AUTOSAR XML (schema 4-2-2)
standard types defined: uint64, uint64_DataConstr
package /ComponentTypes
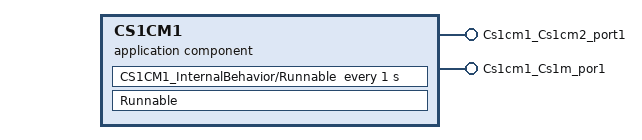
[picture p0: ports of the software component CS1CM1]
  application sw component type CS1CM1
    provide port Cs1cm1_Cs1cm2_port1: nonqueued-sender-com-spec{data-element=Cs1cm1_Cs1cm2_port1/Element, init-value=0}, provided-interface=Cs1cm1_Cs1cm2_port1
    provide port Cs1cm1_Cs1m_por1: nonqueued-sender-com-spec{data-element=Cs1cm1_Cs1m_por1/Element, init-value=0}, provided-interface=Cs1cm1_Cs1m_por1
    behavior CS1CM1_InternalBehavior
      timing event TMT_Runnable: start-on-event=CS1CM1_InternalBehavior/Runnable, period=1
      runnable Runnable: minimum-start-interval=1
        data-send-points:
          access SEND_Cs1cm1_Cs1cm2_port1_Element: accessed-variable=Cs1cm1_Cs1cm2_port1.Element
          access SEND_Cs1cm1_Cs1m_por1_Element: accessed-variable=Cs1cm1_Cs1m_por1.Element
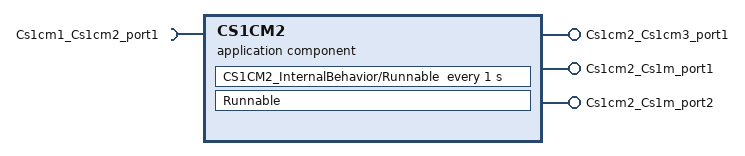
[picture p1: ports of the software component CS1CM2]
  application sw component type CS1CM2
    provide port Cs1cm2_Cs1cm3_port1: server-com-spec{operation=Cs1cm2_Cs1cm3_port1/Operation, queue-length=1}, provided-interface=Cs1cm2_Cs1cm3_port1
    provide port Cs1cm2_Cs1m_port1: nonqueued-sender-com-spec{data-element=Cs1cm2_Cs1m_port1/Element, init-value=0}, provided-interface=Cs1cm2_Cs1m_port1
    provide port Cs1cm2_Cs1m_port2: nonqueued-sender-com-spec{data-element=Cs1cm2_Cs1m_port2/Element, init-value=0}, provided-interface=Cs1cm2_Cs1m_port2
    require port Cs1cm1_Cs1cm2_port1: nonqueued-receiver-com-spec{data-element=Cs1cm1_Cs1cm2_port1/Element, filter=data-filter-type=ALWAYS, init-value=0}, required-interface=Cs1cm1_Cs1cm2_port1
    behavior CS1CM2_InternalBehavior
      timing event TMT_Runnable: start-on-event=CS1CM2_InternalBehavior/Runnable, period=1
      runnable Runnable: minimum-start-interval=1
        data-receive-point-by-arguments:
          access REC_Cs1cm1_Cs1cm2_port1_Element: accessed-variable=Cs1cm1_Cs1cm2_port1.Element
        data-send-points:
          access SEND_Cs1cm2_Cs1m_port1_Element: accessed-variable=Cs1cm2_Cs1m_port1.Element
          access SEND_Cs1cm2_Cs1m_port2_Element: accessed-variable=Cs1cm2_Cs1m_port2.Element
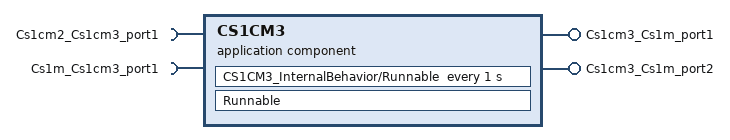
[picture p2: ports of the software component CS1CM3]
  application sw component type CS1CM3
    provide port Cs1cm3_Cs1m_port1: nonqueued-sender-com-spec{data-element=Cs1cm3_Cs1m_port1/Element, init-value=0}, provided-interface=Cs1cm3_Cs1m_port1
    provide port Cs1cm3_Cs1m_port2: nonqueued-sender-com-spec{data-element=Cs1cm3_Cs1m_port2/Element, init-value=0}, provided-interface=Cs1cm3_Cs1m_port2
    require port Cs1cm2_Cs1cm3_port1: client-com-spec=Cs1cm2_Cs1cm3_port1/Operation, required-interface=Cs1cm2_Cs1cm3_port1
    require port Cs1m_Cs1cm3_port1: nonqueued-receiver-com-spec{data-element=Cs1m_Cs1cm3_port1/Element, filter=data-filter-type=ALWAYS, init-value=0}, required-interface=Cs1m_Cs1cm3_port1
    behavior CS1CM3_InternalBehavior
      timing event TMT_Runnable: start-on-event=CS1CM3_InternalBehavior/Runnable, period=1
      runnable Runnable: minimum-start-interval=1
        data-receive-point-by-arguments:
          access REC_Cs1m_Cs1cm3_port1_Element: accessed-variable=Cs1m_Cs1cm3_port1.Element
        data-send-points:
          access SEND_Cs1cm3_Cs1m_port1_Element: accessed-variable=Cs1cm3_Cs1m_port1.Element
          access SEND_Cs1cm3_Cs1m_port2_Element: accessed-variable=Cs1cm3_Cs1m_port2.Element
        sync call SC_Cs1cm2_Cs1cm3_port1_Operation: operation=Cs1cm2_Cs1cm3_port1.Operation, timeout=0
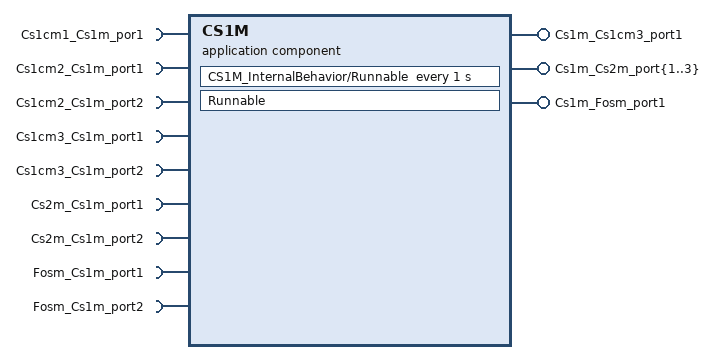
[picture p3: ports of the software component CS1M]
  application sw component type CS1M
    5 x provide port:
      Cs1m_Cs1cm3_port1: nonqueued-sender-com-spec{data-element=Cs1m_Cs1cm3_port1/Element, init-value=0}, provided-interface=Cs1m_Cs1cm3_port1
      Cs1m_Cs2m_port{1..3}: nonqueued-sender-com-spec{data-element=Cs1m_Cs2m_port{1..3}/Element, init-value=0}, provided-interface=Cs1m_Cs2m_port{1..3}
      Cs1m_Fosm_port1: nonqueued-sender-com-spec{data-element=Cs1m_Fosm_port1/Element, init-value=0}, provided-interface=Cs1m_Fosm_port1
    9 x require port:
      Cs1cm1_Cs1m_por1: nonqueued-receiver-com-spec{data-element=Cs1cm1_Cs1m_por1/Element, filter=data-filter-type=ALWAYS, init-value=0}, required-interface=Cs1cm1_Cs1m_por1
      Cs1cm2_Cs1m_port1: nonqueued-receiver-com-spec{data-element=Cs1cm2_Cs1m_port1/Element, filter=data-filter-type=ALWAYS, init-value=0}, required-interface=Cs1cm2_Cs1m_port1
      Cs1cm2_Cs1m_port2: nonqueued-receiver-com-spec{data-element=Cs1cm2_Cs1m_port2/Element, filter=data-filter-type=ALWAYS, init-value=0}, required-interface=Cs1cm2_Cs1m_port2
      Cs1cm3_Cs1m_port1: nonqueued-receiver-com-spec{data-element=Cs1cm3_Cs1m_port1/Element, filter=data-filter-type=ALWAYS, init-value=0}, required-interface=Cs1cm3_Cs1m_port1
      Cs1cm3_Cs1m_port2: nonqueued-receiver-com-spec{data-element=Cs1cm3_Cs1m_port2/Element, filter=data-filter-type=ALWAYS, init-value=0}, required-interface=Cs1cm3_Cs1m_port2
      Cs2m_Cs1m_port1: nonqueued-receiver-com-spec{data-element=Cs2m_Cs1m_port1/Element, filter=data-filter-type=ALWAYS, init-value=0}, required-interface=Cs2m_Cs1m_port1
      Cs2m_Cs1m_port2: nonqueued-receiver-com-spec{data-element=Cs2m_Cs1m_port2/Element, filter=data-filter-type=ALWAYS, init-value=0}, required-interface=Cs2m_Cs1m_port2
      Fosm_Cs1m_port1: nonqueued-receiver-com-spec{data-element=Fosm_Cs1m_port1/Element, filter=data-filter-type=ALWAYS, init-value=0}, required-interface=Fosm_Cs1m_port1
      Fosm_Cs1m_port2: nonqueued-receiver-com-spec{data-element=Fosm_Cs1m_port2/Element, filter=data-filter-type=ALWAYS, init-value=0}, required-interface=Fosm_Cs1m_port2
    behavior CS1M_InternalBehavior
      timing event TMT_Runnable: start-on-event=CS1M_InternalBehavior/Runnable, period=1
      runnable Runnable: minimum-start-interval=1
        data-receive-point-by-arguments:
          9 x access:
            REC_Cs1cm1_Cs1m_por1_Element: accessed-variable=Cs1cm1_Cs1m_por1.Element
            REC_Cs1cm2_Cs1m_port1_Element: accessed-variable=Cs1cm2_Cs1m_port1.Element
            REC_Cs1cm2_Cs1m_port2_Element: accessed-variable=Cs1cm2_Cs1m_port2.Element
            REC_Cs1cm3_Cs1m_port1_Element: accessed-variable=Cs1cm3_Cs1m_port1.Element
            REC_Cs1cm3_Cs1m_port2_Element: accessed-variable=Cs1cm3_Cs1m_port2.Element
            REC_Cs2m_Cs1m_port1_Element: accessed-variable=Cs2m_Cs1m_port1.Element
            REC_Cs2m_Cs1m_port2_Element: accessed-variable=Cs2m_Cs1m_port2.Element
            REC_Fosm_Cs1m_port1_Element: accessed-variable=Fosm_Cs1m_port1.Element
            REC_Fosm_Cs1m_port2_Element: accessed-variable=Fosm_Cs1m_port2.Element
        data-send-points:
          5 x access:
            SEND_Cs1m_Cs1cm3_port1_Element: accessed-variable=Cs1m_Cs1cm3_port1.Element
            SEND_Cs1m_Cs2m_port{1..3}_Element: accessed-variable=Cs1m_Cs2m_port{1..3}.Element
            SEND_Cs1m_Fosm_port1_Element: accessed-variable=Cs1m_Fosm_port1.Element
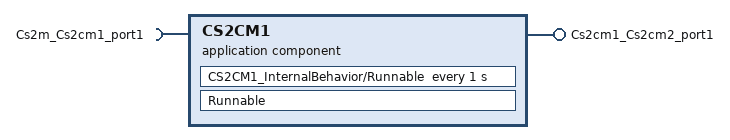
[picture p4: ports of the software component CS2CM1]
  application sw component type CS2CM1
    provide port Cs2cm1_Cs2cm2_port1: nonqueued-sender-com-spec{data-element=Cs2cm1_Cs2cm2_port1/Element, init-value=0}, provided-interface=Cs2cm1_Cs2cm2_port1
    require port Cs2m_Cs2cm1_port1: nonqueued-receiver-com-spec{data-element=Cs2m_Cs2cm1_port1/Element, filter=data-filter-type=ALWAYS, init-value=0}, required-interface=Cs2m_Cs2cm1_port1
    behavior CS2CM1_InternalBehavior
      timing event TMT_Runnable: start-on-event=CS2CM1_InternalBehavior/Runnable, period=1
      runnable Runnable: minimum-start-interval=1
        data-receive-point-by-arguments:
          access REC_Cs2m_Cs2cm1_port1_Element: accessed-variable=Cs2m_Cs2cm1_port1.Element
        data-send-points:
          access SEND_Cs2cm1_Cs2cm2_port1_Element: accessed-variable=Cs2cm1_Cs2cm2_port1.Element
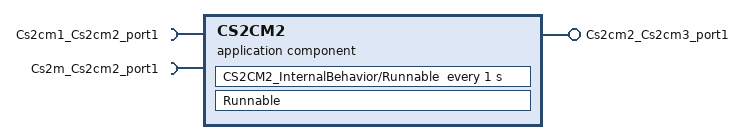
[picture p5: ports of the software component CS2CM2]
  application sw component type CS2CM2
    provide port Cs2cm2_Cs2cm3_port1: nonqueued-sender-com-spec{data-element=Cs2cm2_Cs2cm3_port1/Element, init-value=0}, provided-interface=Cs2cm2_Cs2cm3_port1
    require port Cs2cm1_Cs2cm2_port1: nonqueued-receiver-com-spec{data-element=Cs2cm1_Cs2cm2_port1/Element, filter=data-filter-type=ALWAYS, init-value=0}, required-interface=Cs2cm1_Cs2cm2_port1
    require port Cs2m_Cs2cm2_port1: nonqueued-receiver-com-spec{data-element=Cs2m_Cs2cm2_port1/Element, filter=data-filter-type=ALWAYS, init-value=0}, required-interface=Cs2m_Cs2cm2_port1
    behavior CS2CM2_InternalBehavior
      timing event TMT_Runnable: start-on-event=CS2CM2_InternalBehavior/Runnable, period=1
      runnable Runnable: minimum-start-interval=1
        data-receive-point-by-arguments:
          access REC_Cs2cm1_Cs2cm2_port1_Element: accessed-variable=Cs2cm1_Cs2cm2_port1.Element
          access REC_Cs2m_Cs2cm2_port1_Element: accessed-variable=Cs2m_Cs2cm2_port1.Element
        data-send-points:
          access SEND_Cs2cm2_Cs2cm3_port1_Element: accessed-variable=Cs2cm2_Cs2cm3_port1.Element
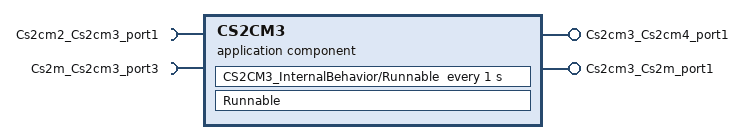
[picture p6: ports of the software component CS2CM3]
  application sw component type CS2CM3
    provide port Cs2cm3_Cs2cm4_port1: nonqueued-sender-com-spec{data-element=Cs2cm3_Cs2cm4_port1/Element, init-value=0}, provided-interface=Cs2cm3_Cs2cm4_port1
    provide port Cs2cm3_Cs2m_port1: nonqueued-sender-com-spec{data-element=Cs2cm3_Cs2m_port1/Element, init-value=0}, provided-interface=Cs2cm3_Cs2m_port1
    require port Cs2cm2_Cs2cm3_port1: nonqueued-receiver-com-spec{data-element=Cs2cm2_Cs2cm3_port1/Element, filter=data-filter-type=ALWAYS, init-value=0}, required-interface=Cs2cm2_Cs2cm3_port1
    require port Cs2m_Cs2cm3_port3: nonqueued-receiver-com-spec{data-element=Cs2m_Cs2cm3_port3/Element, filter=data-filter-type=ALWAYS, init-value=0}, required-interface=Cs2m_Cs2cm3_port3
    behavior CS2CM3_InternalBehavior
      timing event TMT_Runnable: start-on-event=CS2CM3_InternalBehavior/Runnable, period=1
      runnable Runnable: minimum-start-interval=1
        data-receive-point-by-arguments:
          access REC_Cs2cm2_Cs2cm3_port1_Element: accessed-variable=Cs2cm2_Cs2cm3_port1.Element
          access REC_Cs2m_Cs2cm3_port3_Element: accessed-variable=Cs2m_Cs2cm3_port3.Element
        data-send-points:
          access SEND_Cs2cm3_Cs2cm4_port1_Element: accessed-variable=Cs2cm3_Cs2cm4_port1.Element
          access SEND_Cs2cm3_Cs2m_port1_Element: accessed-variable=Cs2cm3_Cs2m_port1.Element
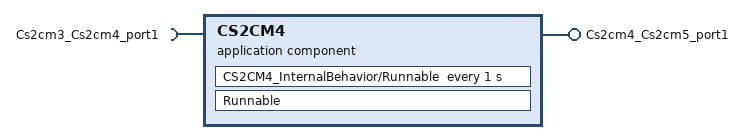
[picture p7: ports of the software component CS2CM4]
  application sw component type CS2CM4
    provide port Cs2cm4_Cs2cm5_port1: server-com-spec{operation=Cs2cm4_Cs2cm5_port1/Operation, queue-length=1}, provided-interface=Cs2cm4_Cs2cm5_port1
    require port Cs2cm3_Cs2cm4_port1: nonqueued-receiver-com-spec{data-element=Cs2cm3_Cs2cm4_port1/Element, filter=data-filter-type=ALWAYS, init-value=0}, required-interface=Cs2cm3_Cs2cm4_port1
    behavior CS2CM4_InternalBehavior
      timing event TMT_Runnable: start-on-event=CS2CM4_InternalBehavior/Runnable, period=1
      runnable Runnable: minimum-start-interval=1
        data-receive-point-by-arguments:
          access REC_Cs2cm3_Cs2cm4_port1_Element: accessed-variable=Cs2cm3_Cs2cm4_port1.Element
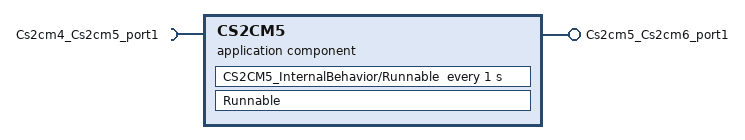
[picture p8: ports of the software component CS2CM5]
  application sw component type CS2CM5
    provide port Cs2cm5_Cs2cm6_port1: server-com-spec{operation=Cs2cm5_Cs2cm6_port1/Operation, queue-length=1}, provided-interface=Cs2cm5_Cs2cm6_port1
    require port Cs2cm4_Cs2cm5_port1: client-com-spec=Cs2cm4_Cs2cm5_port1/Operation, required-interface=Cs2cm4_Cs2cm5_port1
    behavior CS2CM5_InternalBehavior
      timing event TMT_Runnable: start-on-event=CS2CM5_InternalBehavior/Runnable, period=1
      runnable Runnable: minimum-start-interval=1
        sync call SC_Cs2cm4_Cs2cm5_port1_Operation: operation=Cs2cm4_Cs2cm5_port1.Operation, timeout=0
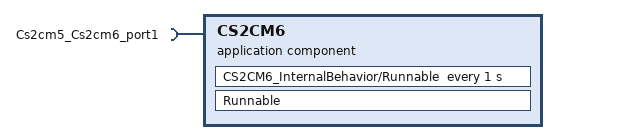
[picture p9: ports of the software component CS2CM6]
  application sw component type CS2CM6
    require port Cs2cm5_Cs2cm6_port1: client-com-spec=Cs2cm5_Cs2cm6_port1/Operation, required-interface=Cs2cm5_Cs2cm6_port1
    behavior CS2CM6_InternalBehavior
      timing event TMT_Runnable: start-on-event=CS2CM6_InternalBehavior/Runnable, period=1
      runnable Runnable: minimum-start-interval=1
        sync call SC_Cs2cm5_Cs2cm6_port1_Operation: operation=Cs2cm5_Cs2cm6_port1.Operation, timeout=0
  application sw component type CS2M
    6 x provide port:
      Cs2m_Cs1m_port1: nonqueued-sender-com-spec{data-element=Cs2m_Cs1m_port1/Element, init-value=0}, provided-interface=Cs2m_Cs1m_port1
      Cs2m_Cs1m_port2: nonqueued-sender-com-spec{data-element=Cs2m_Cs1m_port2/Element, init-value=0}, provided-interface=Cs2m_Cs1m_port2
      Cs2m_Cs2cm1_port1: nonqueued-sender-com-spec{data-element=Cs2m_Cs2cm1_port1/Element, init-value=0}, provided-interface=Cs2m_Cs2cm1_port1
      Cs2m_Cs2cm2_port1: nonqueued-sender-com-spec{data-element=Cs2m_Cs2cm2_port1/Element, init-value=0}, provided-interface=Cs2m_Cs2cm2_port1
      Cs2m_Cs2cm3_port3: nonqueued-sender-com-spec{data-element=Cs2m_Cs2cm3_port3/Element, init-value=0}, provided-interface=Cs2m_Cs2cm3_port3
      Cs2m_Fosm_port1: nonqueued-sender-com-spec{data-element=Cs2m_Fosm_port1/Element, init-value=0}, provided-interface=Cs2m_Fosm_port1
    6 x require port:
      Cs1m_Cs2m_port{1..3}: nonqueued-receiver-com-spec{data-element=Cs1m_Cs2m_port{1..3}/Element, filter=data-filter-type=ALWAYS, init-value=0}, required-interface=Cs1m_Cs2m_port{1..3}
      Cs2cm3_Cs2m_port1: nonqueued-receiver-com-spec{data-element=Cs2cm3_Cs2m_port1/Element, filter=data-filter-type=ALWAYS, init-value=0}, required-interface=Cs2cm3_Cs2m_port1
      Fosm_Cs2m_port1: nonqueued-receiver-com-spec{data-element=Fosm_Cs2m_port1/Element, filter=data-filter-type=ALWAYS, init-value=0}, required-interface=Fosm_Cs2m_port1
      Fosm_Cs2m_Port2: nonqueued-receiver-com-spec{data-element=Fosm_Cs2m_Port2/Element, filter=data-filter-type=ALWAYS, init-value=0}, required-interface=Fosm_Cs2m_Port2
    behavior CS2M_InternalBehavior
      timing event TMT_Runnable: start-on-event=CS2M_InternalBehavior/Runnable, period=1
      runnable Runnable: minimum-start-interval=1
        data-receive-point-by-arguments:
          6 x access:
            REC_Cs1m_Cs2m_port{1..3}_Element: accessed-variable=Cs1m_Cs2m_port{1..3}.Element
            REC_Cs2cm3_Cs2m_port1_Element: accessed-variable=Cs2cm3_Cs2m_port1.Element
            REC_Fosm_Cs2m_port1_Element: accessed-variable=Fosm_Cs2m_port1.Element
            REC_Fosm_Cs2m_Port2_Element: accessed-variable=Fosm_Cs2m_Port2.Element
        data-send-points:
          6 x access:
            SEND_Cs2m_Cs1m_port1_Element: accessed-variable=Cs2m_Cs1m_port1.Element
            SEND_Cs2m_Cs1m_port2_Element: accessed-variable=Cs2m_Cs1m_port2.Element
            SEND_Cs2m_Cs2cm1_port1_Element: accessed-variable=Cs2m_Cs2cm1_port1.Element
            SEND_Cs2m_Cs2cm2_port1_Element: accessed-variable=Cs2m_Cs2cm2_port1.Element
            SEND_Cs2m_Cs2cm3_port3_Element: accessed-variable=Cs2m_Cs2cm3_port3.Element
            SEND_Cs2m_Fosm_port1_Element: accessed-variable=Cs2m_Fosm_port1.Element
  application sw component type FOSM
    4 x provide port:
      Fosm_Cs1m_port1: nonqueued-sender-com-spec{data-element=Fosm_Cs1m_port1/Element, init-value=0}, provided-interface=Fosm_Cs1m_port1
      Fosm_Cs1m_port2: nonqueued-sender-com-spec{data-element=Fosm_Cs1m_port2/Element, init-value=0}, provided-interface=Fosm_Cs1m_port2
      Fosm_Cs2m_port1: nonqueued-sender-com-spec{data-element=Fosm_Cs2m_port1/Element, init-value=0}, provided-interface=Fosm_Cs2m_port1
      Fosm_Cs2m_Port2: nonqueued-sender-com-spec{data-element=Fosm_Cs2m_Port2/Element, init-value=0}, provided-interface=Fosm_Cs2m_Port2
    require port Cs1m_Fosm_port1: nonqueued-receiver-com-spec{data-element=Cs1m_Fosm_port1/Element, filter=data-filter-type=ALWAYS, init-value=0}, required-interface=Cs1m_Fosm_port1
    require port Cs2m_Fosm_port1: nonqueued-receiver-com-spec{data-element=Cs2m_Fosm_port1/Element, filter=data-filter-type=ALWAYS, init-value=0}, required-interface=Cs2m_Fosm_port1
    behavior FOSM_InternalBehavior
      timing event TMT_Runnable: start-on-event=FOSM_InternalBehavior/Runnable, period=1
      runnable Runnable: minimum-start-interval=1
        data-receive-point-by-arguments:
          access REC_Cs1m_Fosm_port1_Element: accessed-variable=Cs1m_Fosm_port1.Element
          access REC_Cs2m_Fosm_port1_Element: accessed-variable=Cs2m_Fosm_port1.Element
        data-send-points:
          4 x access:
            SEND_Fosm_Cs1m_port1_Element: accessed-variable=Fosm_Cs1m_port1.Element
            SEND_Fosm_Cs1m_port2_Element: accessed-variable=Fosm_Cs1m_port2.Element
            SEND_Fosm_Cs2m_port1_Element: accessed-variable=Fosm_Cs2m_port1.Element
            SEND_Fosm_Cs2m_Port2_Element: accessed-variable=Fosm_Cs2m_Port2.Element
  composition sw component type OSDE_Test_Good
    12 x component:
      CS1CM{1..3}_SWC: type=CS1CM{1..3}
      CS1M_SWC: type=CS1M
      CS2CM{1..6}_SWC: type=CS2CM{1..6}
      CS2M_SWC: type=CS2M
      FOSM_SWC: type=FOSM
    connect CS1CM1_SWC.Cs1cm1_Cs1cm2_port1 -> CS1CM2_SWC.Cs1cm1_Cs1cm2_port1
    connect CS1CM1_SWC.Cs1cm1_Cs1m_por1 -> CS1M_SWC.Cs1cm1_Cs1m_por1
    connect CS1CM2_SWC.Cs1cm2_Cs1cm3_port1 -> CS1CM3_SWC.Cs1cm2_Cs1cm3_port1
    connect CS1CM2_SWC.Cs1cm2_Cs1m_port1 -> CS1M_SWC.Cs1cm2_Cs1m_port1
    connect CS1CM2_SWC.Cs1cm2_Cs1m_port2 -> CS1M_SWC.Cs1cm2_Cs1m_port2
    connect CS1CM3_SWC.Cs1cm3_Cs1m_port1 -> CS1M_SWC.Cs1cm3_Cs1m_port1
    connect CS1CM3_SWC.Cs1cm3_Cs1m_port2 -> CS1M_SWC.Cs1cm3_Cs1m_port2
    connect CS1M_SWC.Cs1m_Cs1cm3_port1 -> CS1CM3_SWC.Cs1m_Cs1cm3_port1
    connect CS1M_SWC.Cs1m_Cs2m_port{1..3} -> CS2M_SWC.Cs1m_Cs2m_port{1..3}
    connect CS1M_SWC.Cs1m_Fosm_port1 -> FOSM_SWC.Cs1m_Fosm_port1
    connect CS2CM1_SWC.Cs2cm1_Cs2cm2_port1 -> CS2CM2_SWC.Cs2m_Cs2cm2_port1
    connect CS2CM2_SWC.Cs2cm2_Cs2cm3_port1 -> CS2CM3_SWC.Cs2cm2_Cs2cm3_port1
    connect CS2CM3_SWC.Cs2cm3_Cs2cm4_port1 -> CS2CM4_SWC.Cs2cm3_Cs2cm4_port1
    connect CS2CM3_SWC.Cs2cm3_Cs2m_port1 -> CS2M_SWC.Cs2cm3_Cs2m_port1
    connect CS2CM4_SWC.Cs2cm4_Cs2cm5_port1 -> CS2CM5_SWC.Cs2cm4_Cs2cm5_port1
    connect CS2CM5_SWC.Cs2cm5_Cs2cm6_port1 -> CS2CM6_SWC.Cs2cm5_Cs2cm6_port1
    connect CS2M_SWC.Cs2m_Cs1m_port1 -> CS1M_SWC.Cs2m_Cs1m_port1
    connect CS2M_SWC.Cs2m_Cs1m_port2 -> CS1M_SWC.Cs2m_Cs1m_port2
    connect CS2M_SWC.Cs2m_Cs2cm1_port1 -> CS2CM1_SWC.Cs2m_Cs2cm1_port1
    connect CS2M_SWC.Cs2m_Cs2cm2_port1 -> CS2CM2_SWC.Cs2cm1_Cs2cm2_port1
    connect CS2M_SWC.Cs2m_Cs2cm3_port3 -> CS2CM3_SWC.Cs2m_Cs2cm3_port3
    connect CS2M_SWC.Cs2m_Fosm_port1 -> FOSM_SWC.Cs2m_Fosm_port1
    connect FOSM_SWC.Fosm_Cs1m_port1 -> CS1M_SWC.Fosm_Cs1m_port1
    connect FOSM_SWC.Fosm_Cs1m_port2 -> CS1M_SWC.Fosm_Cs1m_port2
    connect FOSM_SWC.Fosm_Cs2m_port1 -> CS2M_SWC.Fosm_Cs2m_port1
    connect FOSM_SWC.Fosm_Cs2m_Port2 -> CS2M_SWC.Fosm_Cs2m_Port2
  12 x swc implementation:
    CS1CM1_Implementation: behavior=CS1CM1_InternalBehavior
      code-descriptors:
        code Default: artifact-descriptors=autosar-engineering-object={short-label=Default, category=SWSRC}
    CS1CM2_Implementation: behavior=CS1CM2_InternalBehavior
      code-descriptors:
        code Default: artifact-descriptors=autosar-engineering-object={short-label=Default, category=SWSRC}
    CS1CM3_Implementation: behavior=CS1CM3_InternalBehavior
      code-descriptors:
        code Default: artifact-descriptors=autosar-engineering-object={short-label=Default, category=SWSRC}
    CS1M_Implementation: behavior=CS1M_InternalBehavior
      code-descriptors:
        code Default: artifact-descriptors=autosar-engineering-object={short-label=Default, category=SWSRC}
    CS2CM1_Implementation: behavior=CS2CM1_InternalBehavior
      code-descriptors:
        code Default: artifact-descriptors=autosar-engineering-object={short-label=Default, category=SWSRC}
    CS2CM2_Implementation: behavior=CS2CM2_InternalBehavior
      code-descriptors:
        code Default: artifact-descriptors=autosar-engineering-object={short-label=Default, category=SWSRC}
    CS2CM3_Implementation: behavior=CS2CM3_InternalBehavior
      code-descriptors:
        code Default: artifact-descriptors=autosar-engineering-object={short-label=Default, category=SWSRC}
    CS2CM4_Implementation: behavior=CS2CM4_InternalBehavior
      code-descriptors:
        code Default: artifact-descriptors=autosar-engineering-object={short-label=Default, category=SWSRC}
    CS2CM5_Implementation: behavior=CS2CM5_InternalBehavior
      code-descriptors:
        code Default: artifact-descriptors=autosar-engineering-object={short-label=Default, category=SWSRC}
    CS2CM6_Implementation: behavior=CS2CM6_InternalBehavior
      code-descriptors:
        code Default: artifact-descriptors=autosar-engineering-object={short-label=Default, category=SWSRC}
    CS2M_Implementation: behavior=CS2M_InternalBehavior
      code-descriptors:
        code Default: artifact-descriptors=autosar-engineering-object={short-label=Default, category=SWSRC}
    FOSM_Implementation: behavior=FOSM_InternalBehavior
      code-descriptors:
        code Default: artifact-descriptors=autosar-engineering-object={short-label=Default, category=SWSRC}
package /PortInterfaces
  client server interface Cs1cm2_Cs1cm3_port1
    operation Operation
  client server interface Cs2cm4_Cs2cm5_port1
    operation Operation
  client server interface Cs2cm5_Cs2cm6_port1
    operation Operation
  25 x sender receiver interface:
    Cs1cm1_Cs1cm2_port1: invalidation-policy{data-element=Cs1cm1_Cs1cm2_port1/Element, handle-invalid=DONT-INVALIDATE}
      data Element: type=uint64
    Cs1cm1_Cs1m_por1: invalidation-policy{data-element=Cs1cm1_Cs1m_por1/Element, handle-invalid=DONT-INVALIDATE}
      data Element: type=uint64
    Cs1cm2_Cs1m_port1: invalidation-policy{data-element=Cs1cm2_Cs1m_port1/Element, handle-invalid=DONT-INVALIDATE}
      data Element: type=uint64
    Cs1cm2_Cs1m_port2: invalidation-policy{data-element=Cs1cm2_Cs1m_port2/Element, handle-invalid=DONT-INVALIDATE}
      data Element: type=uint64
    Cs1cm3_Cs1m_port1: invalidation-policy{data-element=Cs1cm3_Cs1m_port1/Element, handle-invalid=DONT-INVALIDATE}
      data Element: type=uint64
    Cs1cm3_Cs1m_port2: invalidation-policy{data-element=Cs1cm3_Cs1m_port2/Element, handle-invalid=DONT-INVALIDATE}
      data Element: type=uint64
    Cs1m_Cs1cm3_port1: invalidation-policy{data-element=Cs1m_Cs1cm3_port1/Element, handle-invalid=DONT-INVALIDATE}
      data Element: type=uint64
    Cs1m_Cs2m_port1: invalidation-policy{data-element=Cs1m_Cs2m_port1/Element, handle-invalid=DONT-INVALIDATE}
      data Element: type=uint64
    Cs1m_Cs2m_port2: invalidation-policy{data-element=Cs1m_Cs2m_port2/Element, handle-invalid=DONT-INVALIDATE}
      data Element: type=uint64
    Cs1m_Cs2m_port3: invalidation-policy{data-element=Cs1m_Cs2m_port3/Element, handle-invalid=DONT-INVALIDATE}
      data Element: type=uint64
    Cs1m_Fosm_port1: invalidation-policy{data-element=Cs1m_Fosm_port1/Element, handle-invalid=DONT-INVALIDATE}
      data Element: type=uint64
    Cs2cm1_Cs2cm2_port1: invalidation-policy{data-element=Cs2cm1_Cs2cm2_port1/Element, handle-invalid=DONT-INVALIDATE}
      data Element: type=uint64
    Cs2cm2_Cs2cm3_port1: invalidation-policy{data-element=Cs2cm2_Cs2cm3_port1/Element, handle-invalid=DONT-INVALIDATE}
      data Element: type=uint64
    Cs2cm3_Cs2cm4_port1: invalidation-policy{data-element=Cs2cm3_Cs2cm4_port1/Element, handle-invalid=DONT-INVALIDATE}
      data Element: type=uint64
    Cs2cm3_Cs2m_port1: invalidation-policy{data-element=Cs2cm3_Cs2m_port1/Element, handle-invalid=DONT-INVALIDATE}
      data Element: type=uint64
    Cs2m_Cs1m_port1: invalidation-policy{data-element=Cs2m_Cs1m_port1/Element, handle-invalid=DONT-INVALIDATE}
      data Element: type=uint64
    Cs2m_Cs1m_port2: invalidation-policy{data-element=Cs2m_Cs1m_port2/Element, handle-invalid=DONT-INVALIDATE}
      data Element: type=uint64
    Cs2m_Cs2cm1_port1: invalidation-policy{data-element=Cs2m_Cs2cm1_port1/Element, handle-invalid=DONT-INVALIDATE}
      data Element: type=uint64
    Cs2m_Cs2cm2_port1: invalidation-policy{data-element=Cs2m_Cs2cm2_port1/Element, handle-invalid=DONT-INVALIDATE}
      data Element: type=uint64
    Cs2m_Cs2cm3_port3: invalidation-policy{data-element=Cs2m_Cs2cm3_port3/Element, handle-invalid=DONT-INVALIDATE}
      data Element: type=uint64
    Cs2m_Fosm_port1: invalidation-policy{data-element=Cs2m_Fosm_port1/Element, handle-invalid=DONT-INVALIDATE}
      data Element: type=uint64
    Fosm_Cs1m_port1: invalidation-policy{data-element=Fosm_Cs1m_port1/Element, handle-invalid=DONT-INVALIDATE}
      data Element: type=uint64
    Fosm_Cs1m_port2: invalidation-policy{data-element=Fosm_Cs1m_port2/Element, handle-invalid=DONT-INVALIDATE}
      data Element: type=uint64
    Fosm_Cs2m_port1: invalidation-policy{data-element=Fosm_Cs2m_port1/Element, handle-invalid=DONT-INVALIDATE}
      data Element: type=uint64
    Fosm_Cs2m_Port2: invalidation-policy{data-element=Fosm_Cs2m_Port2/Element, handle-invalid=DONT-INVALIDATE}
      data Element: type=uint64
